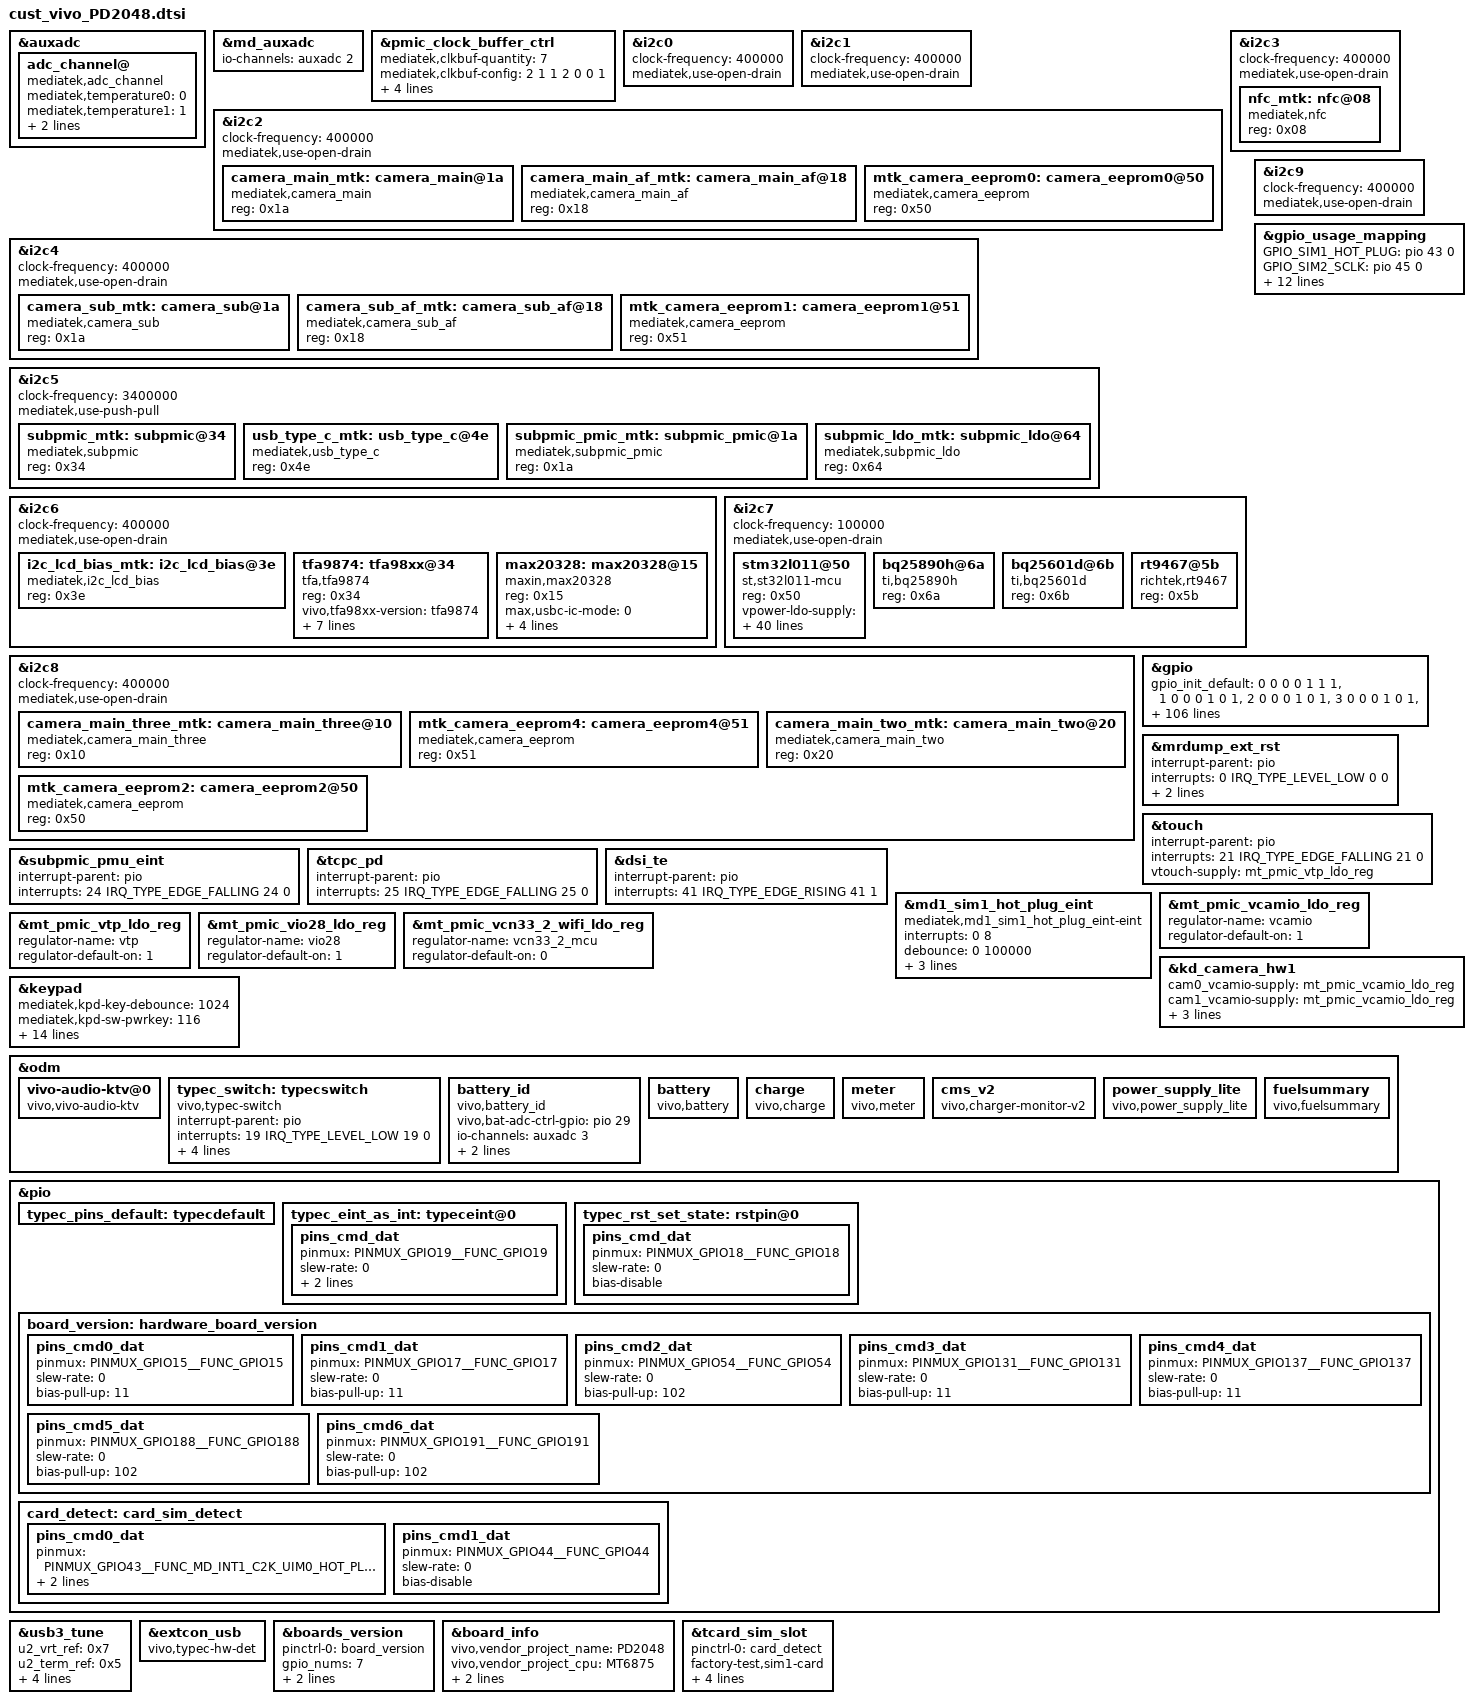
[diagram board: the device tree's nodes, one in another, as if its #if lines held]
/*
 * Generated by MTK SP DrvGen Version: 3.5.160809 for MT6873.
 * 2020-09-28 17:40:00
 * Do Not Modify The File.
 * Copyright Mediatek Inc. (c) 2016.
*/

/*************************
 * ADC DTSI File
*************************/

&auxadc {
	adc_channel@ {
		compatible = "mediatek,adc_channel";
		mediatek,temperature0 = <0>;
		mediatek,temperature1 = <1>;
		mediatek,adc_fdd_rf_params_dynamic_custom_ch = <2>;
		status = "okay";
	};
};
&md_auxadc {
	io-channels = <&auxadc 2>;
};


/*************************
 * CLK_BUF DTSI File
*************************/

&pmic_clock_buffer_ctrl {
	mediatek,clkbuf-quantity = <7>;
	mediatek,clkbuf-config = <2 1 1 2 0 0 1>;
	mediatek,clkbuf-output-impedance = <6 4 4 4 0 0 4>;
	mediatek,clkbuf-controls-for-desense = <0 4 0 4 0 0 0>;
	status = "okay";
};


/*************************
 * I2C DTSI File
*************************/

&i2c0 {
	#address-cells = <1>;
	#size-cells = <0>;
	clock-frequency = <400000>;
	mediatek,use-open-drain;
};

&i2c1 {
	#address-cells = <1>;
	#size-cells = <0>;
	clock-frequency = <400000>;
	mediatek,use-open-drain;
};

&i2c2 {
	#address-cells = <1>;
	#size-cells = <0>;
	clock-frequency = <400000>;
	mediatek,use-open-drain;

	camera_main_mtk:camera_main@1a {
		compatible = "mediatek,camera_main";
		reg = <0x1a>;
		status = "okay";
	};

	camera_main_af_mtk:camera_main_af@18 {
		compatible = "mediatek,camera_main_af";
		reg = <0x18>;
		status = "okay";
	};



	mtk_camera_eeprom0:camera_eeprom0@50 {
		compatible = "mediatek,camera_eeprom";
		reg = <0x50>;
		status = "okay";
	};
};

&i2c3 {
	#address-cells = <1>;
	#size-cells = <0>;
	clock-frequency = <400000>;
	mediatek,use-open-drain;
	nfc_mtk:nfc@08 {
		compatible = "mediatek,nfc";
		reg = <0x08>;
		status = "okay";
	};

};

&i2c4 {
	#address-cells = <1>;
	#size-cells = <0>;
	clock-frequency = <400000>;
	mediatek,use-open-drain;

	camera_sub_mtk:camera_sub@1a {
		compatible = "mediatek,camera_sub";
		reg = <0x1a>;
		status = "okay";
	};
	camera_sub_af_mtk:camera_sub_af@18 {
		compatible = "mediatek,camera_sub_af";
		reg = <0x18>;
		status = "okay";
	};
	 mtk_camera_eeprom1:camera_eeprom1@51 {
		compatible = "mediatek,camera_eeprom";
		reg = <0x51>;
		status = "okay";
	};

};

&i2c5 {
	#address-cells = <1>;
	#size-cells = <0>;
	clock-frequency = <3400000>;
	mediatek,use-push-pull;
	subpmic_mtk:subpmic@34 {
		compatible = "mediatek,subpmic";
		reg = <0x34>;
		status = "okay";
	};

	usb_type_c_mtk:usb_type_c@4e {
		compatible = "mediatek,usb_type_c";
		reg = <0x4e>;
		status = "okay";
	};

	subpmic_pmic_mtk:subpmic_pmic@1a {
		compatible = "mediatek,subpmic_pmic";
		reg = <0x1a>;
		status = "okay";
	};

	subpmic_ldo_mtk:subpmic_ldo@64 {
		compatible = "mediatek,subpmic_ldo";
		reg = <0x64>;
		status = "okay";
	};

};

&i2c6 {
	#address-cells = <1>;
	#size-cells = <0>;
	clock-frequency = <400000>;
	mediatek,use-open-drain;
	i2c_lcd_bias_mtk:i2c_lcd_bias@3e {
		compatible = "mediatek,i2c_lcd_bias";
		reg = <0x3e>;
		status = "okay";
	};

};

&i2c7 {
	#address-cells = <1>;
	#size-cells = <0>;
	clock-frequency = <400000>;
	mediatek,use-open-drain;
};

&i2c8 {
	#address-cells = <1>;
	#size-cells = <0>;
	clock-frequency = <400000>;
	mediatek,use-open-drain;


       	camera_main_three_mtk:camera_main_three@10 {
		compatible = "mediatek,camera_main_three";
		reg = <0x10>;
		status = "okay";
	};

	mtk_camera_eeprom4:camera_eeprom4@51 {
		compatible = "mediatek,camera_eeprom";
		reg = <0x51>;
		status = "okay";
	};

	camera_main_two_mtk:camera_main_two@20 {
		compatible = "mediatek,camera_main_two";
		reg = <0x20>;
		status = "okay";
	};

	mtk_camera_eeprom2:camera_eeprom2@50 {
		compatible = "mediatek,camera_eeprom";
		reg = <0x50>;
		status = "okay";
	};
};

&i2c9 {
	#address-cells = <1>;
	#size-cells = <0>;
	clock-frequency = <400000>;
	mediatek,use-open-drain;




};



/*************************
 * GPIO DTSI File
*************************/

&gpio_usage_mapping {
	GPIO_SIM1_HOT_PLUG = <&pio 43 0>;
	GPIO_SIM2_SCLK = <&pio 45 0>;
	GPIO_SIM2_SRST = <&pio 46 0>;
	GPIO_SIM2_SIO = <&pio 47 0>;
	GPIO_SIM1_SIO = <&pio 48 0>;
	GPIO_SIM1_SRST = <&pio 49 0>;
	GPIO_SIM1_SCLK = <&pio 50 0>;
	GPIO_FDD_BAND_SUPPORT_DETECT_1ST_PIN = <&pio 15 0>;
	GPIO_FDD_BAND_SUPPORT_DETECT_2ND_PIN = <&pio 54 0>;
	GPIO_FDD_BAND_SUPPORT_DETECT_3RD_PIN = <&pio 131 0>;
	GPIO_FDD_BAND_SUPPORT_DETECT_4TH_PIN = <&pio 17 0>;
	GPIO_FDD_BAND_SUPPORT_DETECT_5TH_PIN = <&pio 137 0>;
};

&gpio{
	gpio_init_default = <0 0 0 0 1 1 1>,
		<1 0 0 0 1 0 1>,
		<2 0 0 0 1 0 1>,
		<3 0 0 0 1 0 1>,
		<4 0 0 0 1 1 1>,
		<5 0 0 0 0 0 0>,
		<6 0 0 0 0 0 1>,
		<7 0 1 0 1 0 1>,
		<8 0 1 0 1 0 1>,
		<9 0 0 0 1 1 1>,
		<10 0 1 0 1 0 0>,
		<11 0 0 0 1 0 0>,
		<12 0 1 0 0 0 0>,
		<13 0 0 0 1 0 0>,
		<14 0 1 0 1 0 0>,
		<15 0 0 0 1 1 0>,
		<16 6 0 0 1 0 1>,
		<17 0 0 0 1 1 0>,
		<18 0 0 0 1 0 1>,
		<19 0 0 1 1 1 1>,
		<20 0 1 0 1 0 1>,
		<21 0 0 0 0 0 1>,
		<22 0 0 0 1 0 1>,
		<23 0 0 0 1 1 1>,
		<24 0 0 0 1 1 1>,
		<25 0 0 0 1 1 1>,
		<26 0 1 0 1 0 1>,
		<27 0 1 1 1 0 1>,
		<28 0 1 0 1 0 1>,
		<29 0 1 0 1 0 1>,
		<30 0 1 0 1 0 1>,
		<31 0 0 0 1 1 1>,
		<32 1 0 0 0 0 1>,
		<33 1 0 0 0 0 1>,
		<34 1 0 0 1 0 1>,
		<35 1 0 0 0 0 1>,
		<36 1 0 0 1 0 0>,
		<37 1 0 0 1 0 0>,
		<38 1 0 0 1 0 0>,
		<39 1 0 0 1 0 0>,
		<40 1 0 0 0 0 1>,
		<41 1 0 0 1 0 1>,
		<42 0 1 0 1 0 1>,
		<43 1 0 0 0 0 1>,
		<44 0 0 0 0 0 1>,
		<45 1 0 0 0 0 1>,
		<46 1 0 0 0 0 1>,
		<47 1 0 0 1 1 1>,
		<48 1 0 0 1 1 1>,
		<49 1 0 0 0 0 1>,
		<50 1 0 0 0 0 1>,
		<51 1 0 0 0 0 1>,
		<52 1 0 0 1 1 1>,
		<53 1 0 0 1 1 1>,
		<54 0 0 0 1 1 0>,
		<55 1 0 0 1 1 1>,
		<56 1 0 0 1 1 1>,
		<57 1 0 0 0 0 0>,
		<58 1 0 0 1 0 0>,
		<59 1 0 0 1 0 1>,
		<60 1 0 0 1 0 1>,
		<61 1 0 0 1 0 1>,
		<62 1 0 0 1 0 1>,
		<63 1 0 0 0 0 0>,
		<64 1 0 0 0 0 0>,
		<65 1 0 0 0 0 0>,
		<66 1 0 0 0 0 0>,
		<67 1 0 0 0 0 0>,
		<68 1 0 0 0 0 0>,
		<69 1 0 0 0 0 0>,
		<70 1 0 0 0 0 0>,
		<71 1 0 0 0 0 0>,
		<72 1 0 0 0 0 0>,
		<73 1 0 0 0 0 0>,
		<74 0 0 0 0 0 1>,
		<75 0 0 0 0 0 1>,
		<76 0 0 0 0 0 1>,
		<77 0 0 0 0 0 1>,
		<78 1 0 0 0 0 0>,
		<79 1 0 0 0 0 0>,
		<80 1 0 0 0 0 0>,
		<81 1 0 0 0 0 0>,
		<82 1 0 0 0 0 0>,
		<83 1 0 0 0 0 0>,
		<84 1 0 0 0 0 0>,
		<85 1 0 0 0 0 0>,
		<86 1 0 0 1 0 0>,
		<87 1 0 0 0 0 0>,
		<88 1 0 0 1 0 0>,
		<89 1 0 0 0 0 1>,
		<90 1 0 0 0 0 1>,
		<92 1 0 0 1 1 0>,
		<93 1 0 0 0 0 0>,
		<94 1 0 0 1 1 0>,
		<95 1 0 0 0 0 0>,
		<96 7 0 0 1 0 0>,
		<97 7 0 0 1 0 0>,
		<98 7 0 0 1 0 0>,
		<99 7 0 0 0 0 0>,
		<100 7 0 0 1 0 0>,
		<101 7 0 0 1 0 0>,
		<102 7 0 0 1 0 0>,
		<103 7 0 0 0 0 0>,
		<104 7 0 0 1 0 0>,
		<105 7 0 0 1 0 0>,
		<106 7 0 0 1 0 0>,
		<107 7 0 0 1 0 0>,
		<108 7 0 0 1 0 0>,
		<109 7 0 0 1 0 0>,
		<110 0 1 0 1 0 0>,
		<111 0 1 0 1 0 0>,
		<112 0 1 0 1 0 0>,
		<113 0 1 0 1 0 0>,
		<114 2 0 0 1 0 0>,
		<115 2 0 0 0 0 0>,
		<116 2 0 0 0 0 0>,
		<117 2 0 0 0 0 0>,
		<118 2 0 0 1 1 1>,
		<119 2 0 0 1 1 1>,
		<120 1 0 0 1 1 1>,
		<121 1 0 0 1 1 1>,
		<122 1 0 0 1 1 1>,
		<123 1 0 0 1 1 1>,
		<124 1 0 0 1 1 1>,
		<125 1 0 0 1 1 1>,
		<126 4 0 0 1 0 0>,
		<127 4 0 0 1 0 0>,
		<128 0 1 0 1 0 0>,
		<129 0 1 0 1 0 0>,
		<130 0 1 0 1 0 1>,
		<131 0 0 0 1 1 0>,
		<132 0 1 0 1 0 1>,
		<133 0 1 0 1 0 1>,
		<134 0 1 0 1 0 0>,
		<135 0 1 0 1 0 0>,
		<136 1 0 0 0 0 1>,
		<137 0 0 0 1 1 0>,
		<138 0 0 0 1 1 0>,
		<139 1 0 0 0 0 1>,
		<140 1 0 0 0 0 1>,
		<141 1 0 0 0 0 1>,
		<142 1 0 0 0 0 1>,
		<143 0 1 0 1 0 1>,
		<144 0 1 0 1 0 1>,
		<145 0 1 0 1 0 1>,
		<146 0 1 0 1 0 1>,
		<147 0 1 0 1 0 0>,
		<148 0 1 0 1 0 1>,
		<149 1 0 0 0 0 1>,
		<150 1 0 0 0 0 1>,
		<151 1 0 0 0 0 1>,
		<152 0 0 0 1 0 0>,
		<153 1 0 0 1 0 0>,
		<154 1 0 0 1 1 0>,
		<155 0 0 0 0 0 0>,
		<156 0 0 0 0 0 0>,
		<157 0 1 0 0 0 0>,
		<158 0 1 0 0 0 0>,
		<159 0 1 0 0 0 0>,
		<160 1 0 0 1 1 1>,
		<161 1 0 0 1 1 1>,
		<162 0 0 0 1 0 0>,
		<163 0 0 0 1 0 0>,
		<164 0 0 0 1 0 0>,
		<165 1 0 0 1 0 0>,
		<166 1 0 0 1 0 0>,
		<167 0 0 0 1 0 0>,
		<168 6 0 0 1 0 0>,
		<169 6 0 0 1 0 0>,
		<170 0 1 0 1 0 0>,
		<171 0 1 0 1 0 0>,
		<172 0 0 0 1 0 0>,
		<173 0 0 0 1 0 0>,
		<174 0 0 0 1 0 0>,
		<175 0 0 0 1 0 0>,
		<176 0 0 0 1 0 0>,
		<177 0 0 0 1 0 0>,
		<178 0 0 0 1 0 0>,
		<179 0 0 0 1 0 0>,
		<180 0 0 0 1 0 0>,
		<181 0 0 0 1 0 0>,
		<182 0 0 0 1 0 0>,
		<188 0 0 0 1 1 0>,
		<191 0 0 0 1 1 0>,
		<193 0 1 0 1 0 1>,
		<195 1 0 0 0 0 1>,
		<196 1 0 0 0 0 1>,
		<197 1 0 0 0 0 1>,
		<198 1 0 0 0 0 1>,
		<199 1 0 0 1 0 1>,
		<200 1 0 0 1 1 1>,
		<201 1 0 0 1 1 1>,
		<202 1 0 0 1 1 1>,
		<203 1 0 0 1 1 1>,
		<204 6 0 0 1 0 1>,
		<205 6 0 0 1 0 1>,
		<206 1 0 0 0 0 1>,
		<207 1 0 0 0 0 1>,
		<208 1 0 0 0 0 0>,
		<209 1 0 0 1 0 0>,
		<210 1 0 0 0 0 0>,
		<211 1 0 0 1 0 0>,
		<212 1 0 0 0 0 0>,
		<213 1 0 0 1 0 1>,
		<214 1 0 0 0 0 1>,
		<215 1 0 0 0 0 1>,
		<216 1 0 0 0 0 1>,
		<217 1 0 0 0 0 1>,
		<218 1 0 0 1 0 1>,
		<219 1 0 0 1 0 1>,
		<220 0 0 0 1 0 0>,
		<221 0 0 0 1 0 0>,
		<222 0 0 0 1 0 0>,
		<223 0 0 0 1 0 0>,
		<224 0 0 0 1 0 0>,
		<225 0 0 0 1 0 0>,
		<226 0 0 0 1 0 0>,
		<227 0 0 0 1 0 0>;
};


/*************************
 * EINT DTSI File
*************************/

#include <dt-bindings/interrupt-controller/irq.h>
#include <dt-bindings/interrupt-controller/arm-gic.h>

&mrdump_ext_rst {
	interrupt-parent = <&pio>;
	interrupts = <0 IRQ_TYPE_LEVEL_LOW 0 0>;
	deb-gpios = <&pio 0 0>;
	debounce = <512000>;
	status = "okay";
};

&touch {
	interrupt-parent = <&pio>;
	interrupts = <21 IRQ_TYPE_EDGE_FALLING 21 0>;
	status = "okay";
};

&subpmic_pmu_eint {
	interrupt-parent = <&pio>;
	interrupts = <24 IRQ_TYPE_EDGE_FALLING 24 0>;
	status = "okay";
};

&tcpc_pd {
	interrupt-parent = <&pio>;
	interrupts = <25 IRQ_TYPE_EDGE_FALLING 25 0>;
	status = "okay";
};



&dsi_te {
	interrupt-parent = <&pio>;
	interrupts = <41 IRQ_TYPE_EDGE_RISING 41 1>;
	status = "okay";
};



/*************************
 * MD1_EINT DTSI File
*************************/

&md1_sim1_hot_plug_eint {
	compatible = "mediatek,md1_sim1_hot_plug_eint-eint";
	interrupts = <0 8>;
	debounce = <0 100000>;
	dedicated = <0 0>;
	src_pin = <0 1>;
	sockettype = <0 0>;
	status = "okay";
};



/*************************
 * PMIC DTSI File
*************************/

&mt_pmic_vcamio_ldo_reg {
	regulator-name = "vcamio";
	regulator-default-on = <1>; /* 0:skip, 1: off, 2:on */
	status = "okay";
};
&mt_pmic_vtp_ldo_reg {
	regulator-name = "vtp";
	regulator-default-on = <1>; /* 0:skip, 1: off, 2:on */
	status = "okay";
};
&mt_pmic_vio28_ldo_reg {
	regulator-name = "vio28";
	regulator-default-on = <1>; /* 0:skip, 1: off, 2:on */
	status = "okay";
};

&mt_pmic_vcn33_2_wifi_ldo_reg {
	regulator-name = "vcn33_2_mcu";
	regulator-default-on = <0>;
	status = "okay";
};

&kd_camera_hw1 {
	cam0_vcamio-supply = <&mt_pmic_vcamio_ldo_reg>;
	cam1_vcamio-supply = <&mt_pmic_vcamio_ldo_reg>;
	cam2_vcamio-supply = <&mt_pmic_vcamio_ldo_reg>;
	cam4_vcamio-supply = <&mt_pmic_vcamio_ldo_reg>;
	cam0_vcamaf_def-supply = <&mt_pmic_vio28_ldo_reg>;
	status = "okay";
};

/*zhanghainan add main af pmic power start*/
&camera_main_af_mtk {
	//vcamaf-supply = <&mt_pmic_vio28_ldo_reg>;
	status = "okay";
};
/*zhanghainan add main af pmic power end*/
&touch {
	vtouch-supply = <&mt_pmic_vtp_ldo_reg>;
	status = "okay";
};


/*************************
 * POWER DTSI File
*************************/



/*************************
 * KPD DTSI File
*************************/

&keypad {
	mediatek,kpd-key-debounce = <1024>;
	mediatek,kpd-sw-pwrkey = <116>;
	mediatek,kpd-hw-pwrkey = <8>;
	mediatek,kpd-sw-rstkey  = <114>;
	mediatek,kpd-hw-rstkey = <17>;
	mediatek,kpd-use-extend-type = <0>;
	/*HW Keycode [0~71] -> Linux Keycode*/
	mediatek,kpd-hw-map-num = <72>;
	mediatek,kpd-hw-init-map = <115 0 0 0 0 0 0 0 0 0 0 0 0 0 0 0 0 0 0 0 0 0 0 0 0 0 0 0 0 0 0 0 0 0 0 0 0 0 0 0 0 0 0 0 0 0 0 0 0 0 0 0 0 0 0 0 0 0 0 0 0 0 0 0 0 0 0 0 0 0 0 0 >;
	mediatek,kpd-pwrkey-eint-gpio = <0>;
	mediatek,kpd-pwkey-gpio-din  = <0>;
	mediatek,kpd-hw-dl-key0 = <17>;
	mediatek,kpd-hw-dl-key1 = <0>;
	mediatek,kpd-hw-dl-key2 = <8>;
	mediatek,kpd-hw-recovery-key = <17>;
	mediatek,kpd-hw-factory-key = <0>;
	status = "okay";
};

/*************************
 * qinbaoqiang add for audio start
**************************/
&odm {
	vivo-audio-ktv@0 {
		compatible = "vivo,vivo-audio-ktv";
		status = "okay";
	};

	typec_switch:typecswitch {
		compatible = "vivo,typec-switch";
		interrupt-parent = <&pio>;
		interrupts = <19 IRQ_TYPE_LEVEL_LOW 19 0>;
		deb-gpios = <&pio 19 0>;
		debounce = <256000>;
		pinctrl-names = "default", "typec_eint_as_int";
		pinctrl-0 = <&typec_pins_default>;
		pinctrl-1 = <&typec_eint_as_int>;
		status = "okay";
	};
};

&pio {
	typec_pins_default: typecdefault {
	};
	typec_eint_as_int: typeceint@0 {
		pins_cmd_dat {
			pinmux = <PINMUX_GPIO19__FUNC_GPIO19>;
			slew-rate = <0>;
			bias-pull-up;
			input-enable;
		};
	};
};
&i2c6{
	tfa9874: tfa98xx@34 {
		status = "okay";
		compatible = "tfa,tfa9874";
		#sound-dai-cells = <1>;
		reg = <0x34>;
		vivo,tfa98xx-version = "tfa9874";
		vivo,tfa98xx-config = "tfa98xx_PD2048.cnt";
		vivo,tfa98xx-impedance-min = <6000>;
		vivo,tfa98xx-impedance-max = <10000>;
		vivo,tfa98xx-frequency-min = <600>;
		vivo,tfa98xx-frequency-max = <900>;
		vivo,tfa98xx-Qt-min = <110>;
		reset-gpio = <&pio 30 0>;
	};
};

&i2c6{
	max20328:max20328@15 {
		status = "okay";
		#sound-dai-cells = <0>;
		compatible = "maxin,max20328";
		reg = <0x15>;
		max,usbc-ic-mode = <0>; /* max20328: 0; fsa4480: 1 */
		jack-type = <1>;   /*0:3.5mm, 1:Type-c*/
		switch-type = <0>; /*0:max20328, 1:FS4480*/
		rst-gpio = <&pio 18 0>;
		pinctrl-names = "typec_rst_set_state";
		pinctrl-0 = <&typec_rst_set_state>;
	};
};

&pio {
	typec_rst_set_state:rstpin@0{
			pins_cmd_dat {
				pinmux = <PINMUX_GPIO18__FUNC_GPIO18>;
				slew-rate = <0>;
				bias-disable;
			};
	};
};

/*  qinbaoqiang add end */

/* fengmingli add for usb start */
&usb3_tune {
	u2_vrt_ref = <0x7>;
	u2_term_ref = <0x5>;
	u2_enhance = <0x3>;
	u2_vrt_ref_host = <0x5>;
	u2_term_ref_host = <0x6>;
	u2_enhance_host = <0x2>;
};

&extcon_usb {
	vivo,typec-hw-det;
};
/* fengmingli add for usb end */

/* fuxi add for battery&charge start */
#ifdef CONFIG_VIVO_CHARGING_NEW_ARCH
#ifdef CONFIG_VIVO_CHARGING_DTS_MOVE_HEAD_FILE
&odm {
	battery_id {
		compatible = "vivo,battery_id";
		status = "okay";

		vivo,bat-adc-ctrl-gpio = <&pio 29 0>;

		io-channels = <&auxadc 3>;
		io-channel-names = "battery_id_adc";

		vivo,bat-name = "B-M3 ATL 5000","B-G7 SX 5000","B-G7 ATL 5000","UNKNOWN";
	};

	battery: battery {
		compatible = "vivo,battery";
		status = "okay";
	};

	charge: charge {
		compatible = "vivo,charge";
		status = "okay";
	};

	meter: meter {
		compatible = "vivo,meter";
		status = "okay";
	};

	cms_v2: cms_v2 {
		compatible = "vivo,charger-monitor-v2";
		status = "okay";
	};

	power_supply_lite: power_supply_lite {
		compatible = "vivo,power_supply_lite";
		status = "okay";
	};

	fuelsummary: fuelsummary {
		compatible = "vivo,fuelsummary";
		status = "okay";
	};
};

#else

&battery_id {
	status = "okay";
	compatible = "vivo,battery_id";

	vivo,bat-adc-ctrl-gpio = <&pio 29 0>;

	io-channels = <&auxadc 3>;
	io-channel-names = "battery_id_adc";

	vivo,bat-name = "B-P6 ATL 4020","B-P6 LW 4020","B-G7 ATL 5000","UNKNOWN";
};

&battery {
	status = "okay";
	compatible = "vivo,battery";

	io-channels = <&auxadc 0>,
		<&auxadc 1>;
	io-channel-names = "primary_board_therm",
		"parallel_board_therm";

	vivo,low-volt-threshold = <3400>;
	vivo,soft-rise-percent = <96>;
	vivo,soft-rise-cumulative = <3>;
	vivo,soft-rise-keep-cumulative = <10>;
	vivo,percnet-sync-delta = <5>;
	vivo,percnet-sync-cumulative = <9>;
	vivo,full-sync-cumulative = <3>;
	vivo,soft-term-percent = <99>;
	vivo,soft-term-cumulative = <30>;
};

&charge {
	status = "okay";
	compatible = "vivo,charge";

	vivo,chg-wdt-s = <40>;
	vivo,re-chg-voltage-mv = <100>;
	vivo,prechg-voltage-mv = <3000>;
	vivo,iprechg-current-ma = <300>;
	vivo,iterm-current-ma = <256>;
	vivo,vreg-voltage-mv = <4430>;
	vivo,vindpm-voltage-mv = <4600>;
	vivo,sys-voltage-min-mv= <3300>;
	vivo,boostv-voltage-mv = <5150>;
	vivo,boostv-ilimit-ma = <1500>;
	vivo,ovp-voltage-mv = <15000>;

	vivo,battery-id-vreg-mv = <4430 4430 4430 4430 4430 4430>;
	/*
	 * 0  auto detect charging
	 * 1  vivo-normal chargine
	 * 2  vivo-single engine charging
	 * 3  vivo-dual engine charging
	 * 4  vivo-flash charging
	 */
	vivo,charge-scheme = <0>;
	vivo,direct-charger-enable;

	/*
	 * SUPPORTED_ADAPTER_DEFAULT = 0,
	 * SUPPORTED_ADAPTER_VIVO_LV_DCHG_5V_4500MA = 1,
	 * SUPPORTED_ADAPTER_VIVO_HV_DCHG_10V_2250MA = 2,
	 * SUPPORTED_ADAPTER_QC20__9V_2000MA = 3,
	 * SUPPORTED_ADAPTER_VIVO_HV_DCHG_10V_4000MA = 4,
	 * SUPPORTED_ADAPTER_MAX,
	 */
	vivo,supported-adapter = <3>;

	//parameter for 9V2A
	vivo,primary-ichg-max-ma = <2000>;
	vivo,parallel-ichg-max-ma = <1500>;

	vivo,flashchg-spec-ma = <2000 3300 6000>;
	vivo,fastchg-spec-ma = <2000 2100 3800>;
	vivo,normalchg-spec-ma = <2000 1500 2300>;

	/* 0---PMIC; 1---CHGIC */
	vivo,vbus-detect-source = <1>;

	//vivo,usboe-gpio = <&pio 163 0>;

	/*ffc*/
	//vivo,ffc-enable;
	vivo,ffc-iterm-ma = <(-750)>;
	vivo,ffc-vreg-mv = <4500>;
	vivo,battery-id-ffc-vreg-mv = <4498 4498 4500 4500 4500 4500>;
	vivo,ffc-temperature-range = <150 450>;
	vivo,ffc-full-vbat-table-size = <3>;
	vivo,ffc-full-vbat-table = <4495 4498 4495>;
	vivo,ffc-full-ibat-table-size = <3>;
	vivo,ffc-full-ibat-table = <150 199 (-688)>,
		<200 349 (-911)>,
		<350 449 (-1053)>;
	vivo,battery-id-ffc-full-ibat-table = <(-688) (-727) (-688) (-688) (-688) (-688)>,
		<(-911) (-949) (-911) (-911) (-911) (-911)>,
		<(-1053) (-1091) (-1053) (-1053) (-1053) (-1053)>;
};

&meter {
	status = "okay";
	compatible = "vivo,meter";

	vivo,load-capacity-delta-max = <60>;
	vivo,poweron-delta-capacity = <20>;
	vivo,poweron-low-capacity = <3>;
	vivo,volt-car-delta = <8>;
	vivo,car-volt-delta = <6>;
	vivo,meter-res-compesate = <10>;
	vivo,ocv-board-compesate = <0>;

	/* 0---AGING_UNSUPPORTED; 1---DRIVER_SUPPORTED; 2---USPACE_SUPPORTED */
	vivo,battery-aging-support = <2>;

	vivo,capacity-mAh = <4020>;
	/*COLD_CHG COLD_DISCHG NORMAL_CHG NORMAL_DISCHG*/
	vivo,car-tune-value = <1045 1000 1045 1000>,
		<1045 1000 1045 1000>,
		<1045 1000 1045 1000>,
		<1045 1000 1045 1000>,
		<1045 1000 1045 1000>,
		<1045 1000 1045 1000>;
	vivo,bats-qmax = <3260 3460 3600 3800 3888>,
		<3250 3480 3601 3821 3901>,
		<3350 3566 3716 3860 3886>,
		<3350 3566 3716 3860 3886>,
		<3350 3566 3716 3860 3886>,
		<3350 3566 3716 3860 3886>;

	/* car-tune adjust remap */
	vivo,car-tune-adjust-enable;
	vivo,car-tune-adjust-size = <3>;
	vivo,car-tune-adjust-table = <0 10 (360) 6>,
		<11 20 (-35) 7>,
		<21 100 (-45) 8>;

	#include "bat_setting/PD2048_battery_table.dtsi"
};

&cms_v2 {
	compatible = "vivo,charger-monitor-v2";
	status = "okay";

	default_board: single_charger_board {
		       /*default board: keep in xxxxxx*/
		       support-board-version = "xxxxxx";

		       vivo,bat-det-method = <0>;//r:0, rc:1, eprom:2, ex-fg:3
		       vivo,bat-id-gpio = <&pio 159 0>;

		       //vivo,no-bat-warning;
		       //vivo,no-chg-timeout;
		       vivo,chg-timeout-mins = <900>;

		       //high temperature charger current control enable
		       vivo,htccc-enable;
		       vivo,htccc-data = <46 55 4100000 100000>;

		       //vivo,fbon-scale-enable;/*disable default*/
		       vivo,fbon-scale-data = <2 100 100>;

		       //vivo,switch-scale-enable;/*disable from rom4.0*/
		       vivo,switch-scale-data = <75 53>;

		       vivo,calling-scale-enable;
		       vivo,calling-scale-data = <100 21>;/*ibat:3900 * 0.54 = 2106,more than 1500,not exit dchg*/
		       vivo,calling-dchg-disable;

		       vivo,weixin-calling-scale-enable;
		       vivo,weixin-calling-scale-data = <100 104>;/*5000mA*/

		       //vivo,fixed-scale-enable;
		       vivo,fixed-scale-data = <120 3800 0>;/*dchg fixed time adjust the max ibat,disable default*/

		       /*data processing : batt-temp*/
		       vivo,dp-batt-temp-enable;
		       vivo,dp-batt-temp-data = <100>;

		       /* charging current for devices in exhibition mode */
		       vivo,exhibition-mode-current-primary = <2048>;
		       vivo,exhibition-mode-current-parallel = <0>;

		       /*default tc parameter*/
		       //single charger ibat scale base on temperature battery cell info:1C/1.2C 3960mah
		       /* tmin, tmax, data, volt1, data_ex1, volt2, data_ex2. */
		       vivo,normal-tc-row-col = <10 7>;
		       vivo,normal-tc-data = <550 8888 0 0 0 0 0>,
			       <450 549 50 0 0 0 0>,
			       <200 449 100 4200000 70 0 0>,
			       <150 199 70 0 0 0 0>,
			       <100 149 70 4200000 50 0 0>,
			       <50 99 30 0 0 0 0>,
			       <0 49 30 0 0 0 0>,
			       <(-8888) (-1) 0 0 0 0 0>,
			       <(-8888) (-1) 0 0 0 0 0>,
			       <(-8888) (-1) 0 0 0 0 0>;

		       /*flash tc parameter*/
		       vivo,flash-normal-tc-row-col = <10 7>;
		       vivo,flash-normal-tc-data = <550 8888 0 0 0 0 0>,
			       <450 549 50 0 0 0 0>,
			       <350 449 150 4430000 100 0 0>,
			       <200 349 150 4430000 100 0 0>,
			       <150 199 150 4200000 120 4430000 80>,
			       <100 149 100 0 0 0 0>,
			       <50 99 70 4200000 50 0 0>,
			       <0 49 50 4380000 50 0 0>,
			       <(-50) (-1) 0 0 0 0 0>,
			       <(-8888) (-51) 0 0 0 0 0>;

		       /*adjust fastchg base on board temperature and fb off*/
		       vivo,intell-charge-enable;
		       vivo,parallel-temp-enable = <1 1>;//<x y> x:fb-on y:fb-off

		       /* Flash charge fb-on intell param */
		       vivo,primary-fbon-tc-row-col = <6 3>;
		       vivo,primary-fbon-tc-data = <461 8888 1400>,
			       <441 460 1800>,
			       <411 440 2400>,
			       <401 410 3300>,
			       <381 400 3800>,
			       <(-8888) 380 6000>;

		       vivo,parallel-fbon-tc-row-col = <1 3>;
		       vivo,parallel-fbon-tc-data = <(-8888) 8888 0>;

		       /* Flash charge fb-off intell param */
		       vivo,primary-fboff-tc-row-col = <6 3>;
		       vivo,primary-fboff-tc-data = <450 8888 1800>,
			       <410 449 2500>,
			       <390 409 3600>,
			       <382 389 4500>,
			       <372 381 5000>,
			       <(-8888) 371 6000>;
		       vivo,parallel-fboff-tc-row-col = <1 3>;
		       vivo,parallel-fboff-tc-data = <(-8888) 8888 0>;

		       /* 9v Fast charge fb-on intell param */
		       vivo,9v-primary-fbon-tc-row-col = <6 3>;
		       vivo,9v-primary-fbon-tc-data = <481 8888 500>,
			       <471 480 600>,
			       <451 470 900>,
			       <421 450 1100>,
			       <391 420 1300>,
			       <(-8888) 390 1500>;
		       vivo,9v-parallel-fbon-tc-row-col = <3 3>;
		       vivo,9v-parallel-fbon-tc-data = <401 8888 512>,
			       <386 400 800>,
			       <(-8888) 385 1000>;
		       // second parallel parameter, for rt9467
		       vivo,9v-2nd-parallel-fbon-tc-row-col = <3 3>;
		       vivo,9v-2nd-parallel-fbon-tc-data = <401 8888 512>,
			       <386 400 800>,
			       <(-8888) 385 1000>;


		       /* 9v Fast charge fb-off intell param */
		       vivo,9v-primary-fboff-tc-row-col = <7 3>;
		       vivo,9v-primary-fboff-tc-data = <451 8888 512>,
			       <431 450 512>,
			       <411 430 1200>,
			       <391 410 1350>,
			       <371 390 1600>,
			       <366 370 1800>,
			       <(-8888) 365 2000>;
		       vivo,9v-parallel-fboff-tc-row-col = <6 3>;
		       vivo,9v-parallel-fboff-tc-data = <431 8888 500>,
			       <411 430 700>,
			       <381 410 850>,
			       <371 380 1050>,
			       <351 370 1300>,
			       <(-8888) 350 1500>;
		       // second parallel parameter, for rt9467
		       vivo,9v-2nd-parallel-fboff-tc-row-col = <6 3>;
		       vivo,9v-2nd-parallel-fboff-tc-data = <431 8888 500>,
			       <411 430 700>,
			       <381 410 790>,
			       <371 380 1050>,
			       <351 370 1300>,
			       <(-8888) 350 1500>;


		       /* 5v Normal charge fb-on intell param */
		       vivo,5v-primary-fbon-tc-row-col = <7 3>;
		       vivo,5v-primary-fbon-tc-data = <491 8888 512>,
			       <471 490 1024>,
			       <451 470 1216>,
			       <431 450 1408>,
			       <411 430 1600>,
			       <381 410 1800>,
			       <(-8888) 380 2048>;
		       vivo,5v-parallel-fbon-tc-row-col = <1 3>;
		       vivo,5v-parallel-fbon-tc-data = <(-8888) 8888 0>;

		       /* 5v Normal charge fb-off intell param */
		       vivo,5v-primary-fboff-tc-row-col = <6 3>;
		       vivo,5v-primary-fboff-tc-data = <491 8888 512>,
			       <471 490 1024>,
			       <451 470 1216>,
			       <431 450 1600>,
			       <411 430 1800>,
			       <(-8888) 410 2304>;
		       vivo,5v-parallel-fboff-tc-row-col = <1 3>;
		       vivo,5v-parallel-fboff-tc-data = <(-8888) 8888 0>;

		       // Direct charging param
		       vivo,direct-charger-enable;//porting_check
		       vivo,ex-bms-psy-name = "bq_bms";

		       // bat_baord, usb_conn, pcb_conn(master_bat_conn), bat_conn
		       vivo,dchg-ntc-protect-enable;
		       vivo,dchg-ntc-protect-data = <750 800 850 850>;

		       vivo,adapter-cooldown-data = <900 850 3400>;
		       /*adapter power derate*/
		       vivo,adapter-power-derate-enable;

		       /* usb connecter protect param
			* USB_PROTECT_NONE = 0,
			* USB_CONN_TEMP_HEAT_PROTECT = BIT(0),
			* USB_ID_PROTECT = BIT(1),
			*/
		       vivo,usb-connecter-protect-enable = <1>;
		       vivo,usb-id-protect-data= <1100 1547 500>;/* 500K, 2M, fcc */
		       vivo,usb-conn-heat-protect-data-row-col = <2 4>;
		       vivo,usb-conn-heat-protect-data= <260 8888 670 620>,
			       <(-8888) 259 570 520>;

		       /*
			* max vbus of adapter:11v, max ibus of adapter:5A
			* min voltage of battery for half chg:3500mV,max voltage of battery for half charge:4100mV,
			* 5V2A charge min current threshold: 1000mA,5V2A charge max current threshold:2100mA,
			* flash charge min current threshold:5000mA,flash charge max current threshold:11000mA
			*/

		       /*default parameter*/
		       vivo,charge-param-judge-threshold = <5 2 3500 4300 1000 2100 5000 11000>;
		       /* factory mode charging test param */
		       vivo,charge-test-param-row-col = <12 3>;
		       vivo,charge-test-param-data = <0 0 5500>, /* cable resistance, min value, max value */
			       <0 0 5500>, /* master ibus, min ibus, max ibus */
			       <0 0 5500>, /* slave ibus, min ibus, max ibus */
			       <1 20 40>, /* batt therm ntc, min value, max value */
			       <1 20 45>, /* board therm ntc, min value, max value */
			       <0 20 50>, /* sub charger ntc, min value, max value */
			       <0 20 45>, /* usb con ntc, min value, max value */
			       <0 20 45>, /* usb con 1 ntc, double usb NTC, min value, max value */
			       <0 20 45>, /* bat btb master ntc, min value, max value */
			       <0 20 50>, /* bat btb sub ntc, min value, max value */
			       <0 20 50>, /* bat board ntc, min value, max value */
			       <0 20 50>; /* wireless charge coil ntc, min value, max value */

		       /*flash parameter*/
		       vivo,flash-charge-param-judge-threshold = <11 3 3500 4100 1000 2200 4000 6100>;
		       /* factory mode charging test param */
		       vivo,flash-charge-test-param-row-col = <12 3>;
		       vivo,flash-charge-test-param-data = <1 0 5500>, /* cable resistance, min value, max value */
			       <1 0 5500>, /* master ibus, min ibus, max ibus */
			       <0 0 5500>, /* slave ibus, min ibus, max ibus */
			       <1 20 40>, /* batt therm ntc, min value, max value */
			       <1 20 45>, /* board therm ntc, min value, max value */
			       <0 20 50>, /* sub charger ntc, min value, max value */
			       <1 20 45>, /* usb con ntc, min value, max value */
			       <0 20 45>, /* usb con 1 ntc, double usb NTC, min value, max value */
			       <1 20 45>, /* bat btb master ntc, min value, max value */
			       <0 20 50>, /* bat btb sub ntc, min value, max value */
			       <0 20 50>, /* bat board ntc, min value, max value */
			       <0 20 50>; /* wireless charge coil ntc, min value, max value */
	       };
};

&power_supply_lite {
	status = "okay";
	compatible = "vivo,power_supply_lite";
};

&fuelsummary {
	status = "okay";
	compatible = "vivo,fuelsummary";

	/************************************************************
	 *
	 *  0   vivo-fastchg
	 *  1   qcom-dualchg
	 *  2   mtk-dualchg
	 *  3   qcom-normchg
	 *  4   mtk-normchg
	 *
	 ***********************************************************/
	chg-scheme = <2>;
	fex-version = <3>;
	fbon-ibat = <(-900)>;
	fboff-ibat = <(-1000)>;

	/* 0---AGING_UNSUPPORTED; 1---DRIVER_SUPPORTED; 2---USPACE_SUPPORTED */
	vivo,battery-aging-support = <2>;
};

#endif

&i2c7 {
	#address-cells = <1>;
	#size-cells = <0>;
	status = "okay";
	clock-frequency = <100000>;

	stm32l011@50 {
		compatible = "st,st32l011-mcu";
		reg = <0x50>;

		vpower-ldo-supply = <&mt_pmic_vcn33_2_wifi_ldo_reg>;
		//vivo,power-gpio = <&pio 27 0>;//ZC_LDO_EN
		vivo,int-gpio = <&pio 6 0>;//MCU_INT_AP
		//vivo,usbsel-gpio = <&pio 13 0>;//USB_SW_EN
		vivo,shift-en-gpio = <&pio 12 0>;//SHIFT_EN
		vivo,chg-version-gpio = <&pio 138 0>;//vivo,ln8000-support;
		//vivo,sbu-pwr-gpio = <&pio 20 0>;
		ti,temp-cold-degc = <2>;
		ti,temp-hot-degc = <43>;
		vivo,total-limit-max-ma = <6000>;
		vivo,bigdata-collect-time-limit = <95>;//seconds
		vivo,direct-charger-enable;//porting_check

		/*FFC charge: */
		vivo,ffc-support;
		vivo,ffc-temperature-range = <150 450>;
		//vivo,ffc-param-tuning-enable = <1963>;
		vivo,ffc-cc-to-cv-ibat-thr-rc = <1 3>;
		/*<Tmin Tmax current>*/
		vivo,ffc-cc-to-cv-ibat-thr-table = <150 450 4900>;
		vivo,ffc-dchg-cv-mv-rc = <3 2>;
		/*btb_cv,fg_cv*/
		vivo,ffc-dchg-cv-mv-table = <4450 4430>,/*default*/
			<4510 4510>,/*single_charging*/
			<4510 4480>;/*dual_charging*/
		vivo,battery-id-ffc-dchg-btb_cv-mv-table = <4510 4510 4510 4510 4510 4510>;
		vivo,battery-id-ffc-dchg-fg_cv-mv-table = <4510 4498 4480 4480 4480 4480>;

		vivo,cout-int-gpio = <&pio 5 0>;

		vivo,sbu-cable-id-detect-enable;

		vivo,bat-board-temp-enable = <1>;
		vivo,usb-conn-temp-enable = <1>;
		vivo,bat-conn-temp-enable = <1>;

		vivo,master-bat-conn-temp-enable = <2>;
		vivo,dchg-exit-ntc-threshold = <700 650 700 700 1200>;

		/* BQ25970_SINGLE_DCHG:
		 * DCHG_SINGLE_TYPE_22P5W = 0,
		 * DCHG_SINGLE_TYPE_33W = 1,
		 * DCHG_SINGLE_TYPE_44W = 2,
		 * BQ25970_DUAL_DCHG:DCHG_DUAL_TYPE_44W = 3,
		 */
		vivo,dchg-supported-type = <1>;
		/*adapter power derate*/
		vivo,adapter-power-derate-enable;

		//vivo,single-charger-enable;
		vivo,adapter-sha-encryption;

		io-channels = <&auxadc 4>,
			<&auxadc 5>;

		io-channel-names = "sbu2_cable_id_adc",
			"sbu1_cable_id_adc";

		/*cable r limit table :
		  <rmin,rmax, dchg_ibus_max, cable_id_type, limit_count>
		  cable_id_type: 0:effective cable id, 1:other(default) cable id
		 */
		vivo,cable-r-limit-table-rc = <9 5>;
		vivo,cable-r-limit-table = <(-8888) 271 4000 0 0>,
			<272 329 3000 0 0>,
			<330 394 2250 0 0>,
			<395 505 1800 0 0>,
			<506 8888 0 0 0>,
			<(-8888) 329 3000 1 0>,
			<330 394 2250 1 0>,
			<395 505 1800 1 0>,
			<506 8888 0 1 0>;

		/*load firmware profile*/
		vivo,fw-id-range-pct = <100>;
		#include "bat_setting/mcu-firmware-data-ln8000.dtsi"
		#include "bat_setting/mcu-firmware-data-44w.dtsi"
	};

	bq25890h@6a {
		compatible = "ti,bq25890h";
		reg = <0x6a>;

		//vivo,int-gpio = <&pio 11 0>;
	};

	bq25601d@6b {
		compatible = "ti,bq25601d";
		reg = <0x6b>;

		//vivo,int-gpio = <&pio 11 0>;
		//vivo,enable-gpio = <&pio 69 0>;
	};

	rt9467@5b {
		compatible = "richtek,rt9467";
		reg = <0x5b>;

		//vivo,int-gpio = <&pio 3 0>;
		//vivo,enable-gpio = <&pio 166 0>;
	};
};
#endif
/* fuxi add for battery&charge end */


&boards_version {
	pinctrl-names = "default";
	pinctrl-0 = <&board_version>;
	gpio_nums = <7>;
	gpios = <15 17 54 131 137 188 191>;
	gpios_start = <&pio 15 0>;
};

&board_info {
	vivo,vendor_project_name = "PD2048";
	vivo,vendor_project_cpu = "MT6875";
	vivo,vendor_project_freq = "2.6";
	vivo,vendor_project_cpunum = <8>;
};

&tcard_sim_slot {
	pinctrl-names = "default";
	pinctrl-0 = <&card_detect>;
        factory-test,sim1-card;
        factory-test,sim2-card;
	//factory-test,tf-card;
	vivo,new_card_detect;
        card-detect-sim1,gpios = <&pio 43 0x0>;
        card-detect-sim2,gpios = <&pio 43 0x0>;
	//card-detect-tf-card,gpios = <&pio 18 0x0>;
};

&pio {
	board_version: hardware_board_version {
		pins_cmd0_dat {
			pinmux = <PINMUX_GPIO15__FUNC_GPIO15>;
			slew-rate = <0>;
			bias-pull-up = <11>;
		};
		pins_cmd1_dat {
			pinmux = <PINMUX_GPIO17__FUNC_GPIO17>;
			slew-rate = <0>;
			bias-pull-up = <11>;
		};
		pins_cmd2_dat {
			pinmux = <PINMUX_GPIO54__FUNC_GPIO54>;
			slew-rate = <0>;
			bias-pull-up = <102>;
		};
		pins_cmd3_dat {
			pinmux = <PINMUX_GPIO131__FUNC_GPIO131>;
			slew-rate = <0>;
			bias-pull-up = <11>;
		};
		pins_cmd4_dat {
			pinmux = <PINMUX_GPIO137__FUNC_GPIO137>;
			slew-rate = <0>;
			bias-pull-up = <11>;
		};
		pins_cmd5_dat {
			pinmux = <PINMUX_GPIO188__FUNC_GPIO188>;
			slew-rate = <0>;
			bias-pull-up = <102>;
		};
		pins_cmd6_dat {
			pinmux = <PINMUX_GPIO191__FUNC_GPIO191>;
			slew-rate = <0>;
			bias-pull-up = <102>;
		};
	};

	card_detect: card_sim_detect {
		pins_cmd0_dat {
			pinmux = <PINMUX_GPIO43__FUNC_MD_INT1_C2K_UIM0_HOT_PLUG>;
			slew-rate = <0>;
			bias-disable;
		};
		pins_cmd1_dat {
			pinmux = <PINMUX_GPIO44__FUNC_GPIO44>;
			slew-rate = <0>;
			bias-disable;
		};
		//pins_cmd2_dat {
		//	pinmux = <PINMUX_GPIO18__FUNC_GPIO18>;
		//	slew-rate = <0>;
		//	bias-disable;
		//};
	};
};

